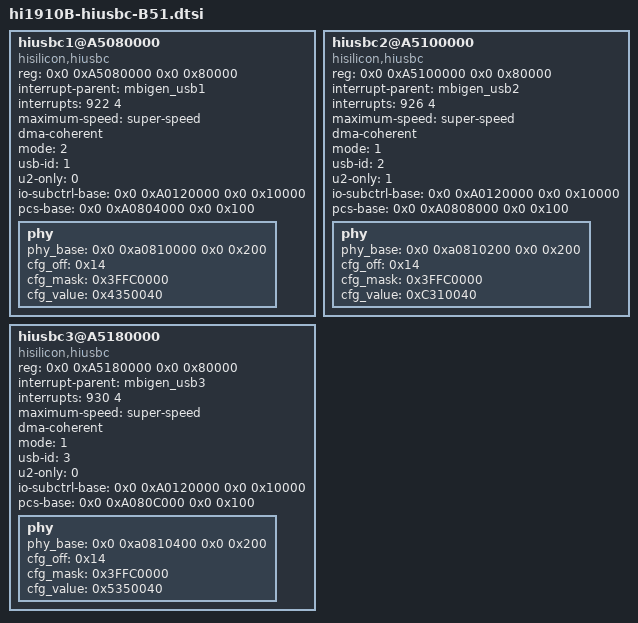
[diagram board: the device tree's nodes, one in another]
/*
hiusbc0@A5000000 {
    compatible = "hisilicon,hiusbc";
    reg = <0x0 0xA5000000 0x0 0x80000>;    // USB_CTRL0 BASE
    interrupt-parent = <&mbigen_usb0>;
    interrupts = <918 4>;
    maximum-speed = "super-speed";
    dma-coherent;
    mode = <1>;                             // 1:host 2:device
    usb-id = <0>;                           // USB Controller id
    u2-only = <0>;
    //u3-only = <1>;
    io-subctrl-base = <0x0 0xA0120000 0x0 0x10000>;
    pcs-base = <0x0 0xA0800000 0x0 0x100>;
    pinctrl-names = "default";
    pinctrl-0 = <&iomg048_io_pmx_func>;
    //gpios = <&gpio2 0x14 0>;
    //gpios-host-value = <1>;
    //gpios-device-value = <0>;
    //gpios-suspend-value = <0>;
};
*/

// 20T Type-C
hiusbc1@A5080000 {
    compatible = "hisilicon,hiusbc";
    reg = <0x0 0xA5080000 0x0 0x80000>;    // USB_CTRL1 BASE
    interrupt-parent = <&mbigen_usb1>;
    interrupts = <922 4>;
    maximum-speed = "super-speed";
    dma-coherent;
    mode = <2>;                             // 1:host 2:device
    usb-id = <1>;                           // USB Controller id
    u2-only = <0>;
    io-subctrl-base = <0x0 0xA0120000 0x0 0x10000>;
    pcs-base = <0x0 0xA0804000 0x0 0x100>;
    phy {
        phy_base = <0x0 0xa0810000 0x0 0x200>;
        cfg_off = <0x14>;
        cfg_mask = <0x3FFC0000>;
        cfg_value = <0x4350040>;
    };
};

// 20T: WIFI-BT
hiusbc2@A5100000 {
    compatible = "hisilicon,hiusbc";
    reg = <0x0 0xA5100000 0x0 0x80000>;    // USB_CTRL2 BASE
    interrupt-parent = <&mbigen_usb2>;
    interrupts = <926 4>;
    maximum-speed = "super-speed";
    dma-coherent;
    mode = <1>;                             // 1:host 2:device
    usb-id = <2>;                           // USB Controller id
    u2-only = <1>;
    io-subctrl-base = <0x0 0xA0120000 0x0 0x10000>;
    pcs-base = <0x0 0xA0808000 0x0 0x100>;

    phy {
        phy_base = <0x0 0xa0810200 0x0 0x200>;
        cfg_off = <0x14>;
        cfg_mask = <0x3FFC0000>;
        cfg_value = <0xC310040>;
    };
};

// 20T: USB Hub
hiusbc3@A5180000 {
    compatible = "hisilicon,hiusbc";
    reg = <0x0 0xA5180000 0x0 0x80000>;    // USB_CTRL3 BASE
    interrupt-parent = <&mbigen_usb3>;
    interrupts = <930 4>;
    maximum-speed = "super-speed";
    dma-coherent;
    mode = <1>;                             // 1:host 2:device
    usb-id = <3>;                           // USB Controller id
    u2-only = <0>;
    io-subctrl-base = <0x0 0xA0120000 0x0 0x10000>;
    pcs-base = <0x0 0xA080C000 0x0 0x100>;

    phy {
        phy_base = <0x0 0xa0810400 0x0 0x200>;
        cfg_off = <0x14>;
        cfg_mask = <0x3FFC0000>;
        cfg_value = <0x5350040>;
    };
};
